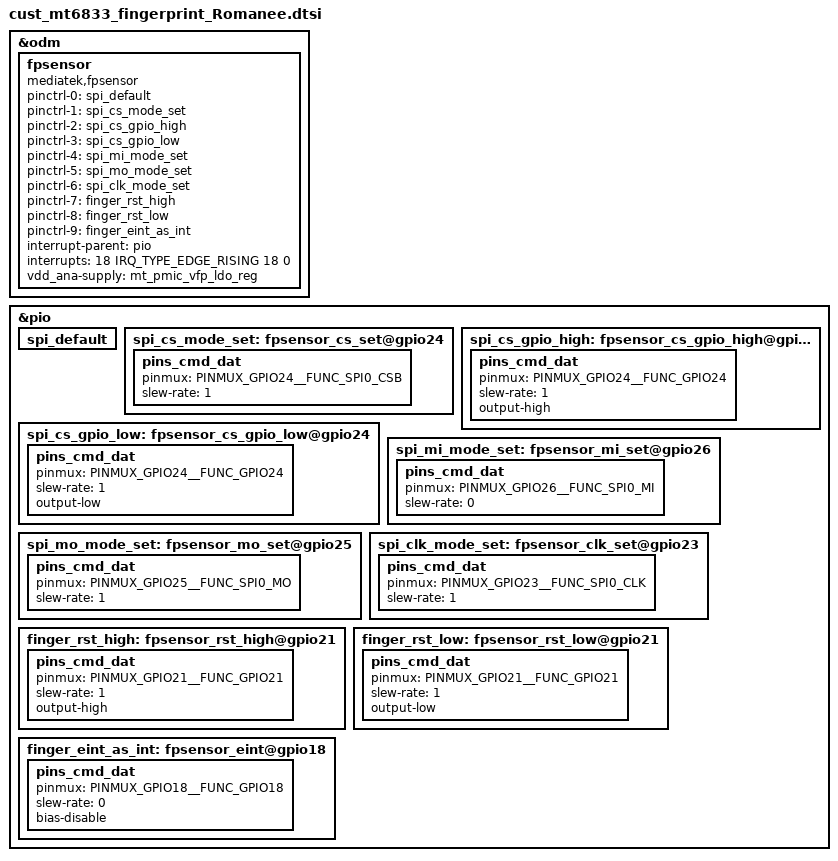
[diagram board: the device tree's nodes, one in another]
/**
* Chipone fpsensor GPIO define. begjin.
**/

&odm {
	fpsensor:fpsensor {
	    compatible = "mediatek,fpsensor";
    };
};

/*
&spi0 {
     #address-cells = <1>;
     #size-cells = <0>;
	   chipone@0{
		     compatible = "mediatek,chipone_fp";
		     reg = <0x0>;
		     spi-max-frequency = <8000000>;
		     status = "okay";
	};
};
*/

&pio {
	spi_default: spi_default {
	};
	spi_cs_mode_set: fpsensor_cs_set@gpio24 {
		pins_cmd_dat {
			pinmux = <PINMUX_GPIO24__FUNC_SPI0_CSB>;
			slew-rate = <1>;
		};
	};
	spi_cs_gpio_high: fpsensor_cs_gpio_high@gpio24 {
		pins_cmd_dat {
			pinmux = <PINMUX_GPIO24__FUNC_GPIO24>;
			slew-rate = <1>;
			output-high;
		};
	};
	spi_cs_gpio_low: fpsensor_cs_gpio_low@gpio24 {
		pins_cmd_dat {
			pinmux = <PINMUX_GPIO24__FUNC_GPIO24>;
			slew-rate = <1>;
			output-low;
		};
	};

	spi_mi_mode_set: fpsensor_mi_set@gpio26 {
		pins_cmd_dat {
			pinmux = <PINMUX_GPIO26__FUNC_SPI0_MI>;
			slew-rate = <0>;
		};
	};

	spi_mo_mode_set: fpsensor_mo_set@gpio25 {
		pins_cmd_dat {
			pinmux = <PINMUX_GPIO25__FUNC_SPI0_MO>;
			slew-rate = <1>;
		};
	};
	
	spi_clk_mode_set: fpsensor_clk_set@gpio23{
		pins_cmd_dat {
			pinmux = <PINMUX_GPIO23__FUNC_SPI0_CLK>;
			slew-rate = <1>;
		};
	};
	
	finger_rst_high: fpsensor_rst_high@gpio21 {
        pins_cmd_dat {
			pinmux = <PINMUX_GPIO21__FUNC_GPIO21>;
            slew-rate = <1>;
            output-high;
        };
    };
   finger_rst_low: fpsensor_rst_low@gpio21 {
        pins_cmd_dat {
			pinmux = <PINMUX_GPIO21__FUNC_GPIO21>;
            slew-rate = <1>;
            output-low;
        };
    };

	finger_eint_as_int: fpsensor_eint@gpio18 {
		pins_cmd_dat {
			pinmux = <PINMUX_GPIO18__FUNC_GPIO18>;
			slew-rate = <0>;
			bias-disable;
		};
	};

};

&fpsensor{
	pinctrl-names = "spi_default","fpsensor_cs_set","fpsensor_cs_gpio_high","fpsensor_cs_gpio_low","fpsensor_mi_set","fpsensor_mo_set",
					        "fpsensor_clk_set","fpsensor_rst_high","fpsensor_rst_low","fpsensor_eint";
	pinctrl-0 = <&spi_default>;
	pinctrl-1 = <&spi_cs_mode_set>;
	pinctrl-2 = <&spi_cs_gpio_high>;
	pinctrl-3 = <&spi_cs_gpio_low>;
	pinctrl-4 = <&spi_mi_mode_set>;
	pinctrl-5 = <&spi_mo_mode_set>;
	pinctrl-6 = <&spi_clk_mode_set>;
	pinctrl-7 = <&finger_rst_high>;
	pinctrl-8 = <&finger_rst_low>;
	pinctrl-9 = <&finger_eint_as_int>;

	interrupt-parent = <&pio>;
	interrupts = <18 IRQ_TYPE_EDGE_RISING 18 0>;
    //debounce = <18 0>;
	vdd_ana-supply = <&mt_pmic_vfp_ldo_reg>;
    status = "okay";
};

